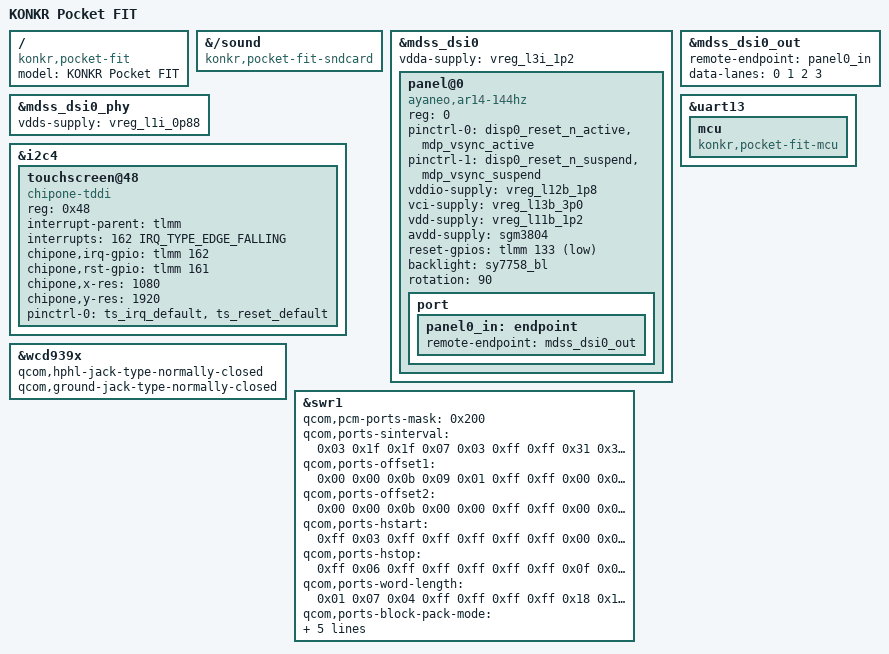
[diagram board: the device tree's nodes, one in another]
// SPDX-License-Identifier: BSD-3-Clause
/*
 * Copyright (c) 2023, Linaro Limited
 * Copyright (c) 2025, Kancy Joe <kancy2333@outlook.com>
 */

/dts-v1/;

#include "sm8650-ayaneo-common.dtsi"

/ {
	model = "KONKR Pocket FIT";
	compatible = "konkr,pocket-fit", "qcom,sm8650";
};

&{/sound} {
	compatible = "konkr,pocket-fit-sndcard";
};

&mdss_dsi0 {
	status = "okay";
	vdda-supply = <&vreg_l3i_1p2>;

	panel@0 {
		status = "okay";
		compatible = "ayaneo,ar14-144hz";
		reg = <0>;
		pinctrl-names = "default", "sleep";
		pinctrl-0 = <&disp0_reset_n_active>, <&mdp_vsync_active>;
		pinctrl-1 = <&disp0_reset_n_suspend>, <&mdp_vsync_suspend>;

		vddio-supply = <&vreg_l12b_1p8>;
		vci-supply = <&vreg_l13b_3p0>;
		vdd-supply = <&vreg_l11b_1p2>;
		avdd-supply = <&sgm3804>;

		reset-gpios = <&tlmm 133 GPIO_ACTIVE_LOW>;
		backlight = <&sy7758_bl>;
		rotation = <90>;

		port {
			panel0_in: endpoint {
				remote-endpoint = <&mdss_dsi0_out>;
			};
		};
	};
};

&mdss_dsi0_out {
	remote-endpoint = <&panel0_in>;
	data-lanes = <0 1 2 3>;
};

&mdss_dsi0_phy {
	vdds-supply = <&vreg_l1i_0p88>;

	status = "okay";
};

/*
 * Touchscreen: ChipOne ICNL9922C TDDI controller.
 *
 * Wiring taken verbatim from the stock Android devicetree
 * (qupv3_1 i2c@a90000 -> mainline &i2c4, device @0x48):
 *   - IRQ:   TLMM gpio162  (ts_irq_default pin state, defined in the dtsi)
 *   - reset: TLMM gpio161  (ts_reset_default pin state, defined in the dtsi)
 *   - power: shared with the panel rails (TDDI), already enabled above,
 *            so no dedicated regulator supply is needed here.
 *
 * Properties use the vendor "chipone-tddi" binding to match the ported
 * chipone_tddi driver. These may be migrated to a mainline-style binding
 * (interrupts + reset-gpios) once the driver port is finalized.
 */
&i2c4 {
	touchscreen@48 {
		compatible = "chipone-tddi";
		reg = <0x48>;

		interrupt-parent = <&tlmm>;
		interrupts = <162 IRQ_TYPE_EDGE_FALLING>;

		chipone,irq-gpio = <&tlmm 162 GPIO_ACTIVE_HIGH>;
		chipone,rst-gpio = <&tlmm 161 GPIO_ACTIVE_HIGH>;
		chipone,x-res = <1080>;
		chipone,y-res = <1920>;

		pinctrl-names = "default";
		pinctrl-0 = <&ts_irq_default>, <&ts_reset_default>;

		status = "okay";
	};
};

&uart13 {
	mcu {
		compatible = "konkr,pocket-fit-mcu";
	};
};

&wcd939x {
	qcom,hphl-jack-type-normally-closed;
	qcom,ground-jack-type-normally-closed;
};

/*
 * HPH PCM ("HiFi") playback, which the UCM profile uses on this board because
 * the PDM path hisses: the RX macro sends the PCM stream on master port 9 (the
 * stock Android swr-port-mapping, and the FIT Elite's), which sm8650.dtsi
 * leaves unconfigured. Give port 9 the PCM timing sm8650.dtsi has at port 8
 * (the FIT Elite's port 9 values) and the PCM data format enable.
 */
&swr1 {
	qcom,pcm-ports-mask = <0x200>;
	qcom,ports-sinterval =		/bits/ 16 <0x03 0x1f 0x1f 0x07 0x03 0xff 0xff 0x31 0x31 0xff 0xff 0xff>;
	qcom,ports-offset1 =		/bits/ 8 <0x00 0x00 0x0b 0x09 0x01 0xff 0xff 0x00 0x00 0xff 0xff 0xff>;
	qcom,ports-offset2 =		/bits/ 8 <0x00 0x00 0x0b 0x00 0x00 0xff 0xff 0x00 0x00 0xff 0xff 0xff>;
	qcom,ports-hstart =		/bits/ 8 <0xff 0x03 0xff 0xff 0xff 0xff 0xff 0x00 0x00 0xff 0xff 0xff>;
	qcom,ports-hstop =		/bits/ 8 <0xff 0x06 0xff 0xff 0xff 0xff 0xff 0x0f 0x0f 0xff 0xff 0xff>;
	qcom,ports-word-length =	/bits/ 8 <0x01 0x07 0x04 0xff 0xff 0xff 0xff 0x18 0x18 0xff 0xff 0xff>;
	qcom,ports-block-pack-mode =	/bits/ 8 <0xff 0x00 0x01 0xff 0xff 0xff 0xff 0x01 0x01 0xff 0xff 0xff>;
	qcom,ports-block-group-count =	/bits/ 8 <0xff 0xff 0xff 0x01 0x03 0xff 0xff 0x00 0x00 0xff 0xff 0xff>;
	qcom,ports-lane-control =	/bits/ 8 <0x01 0x00 0x00 0x00 0x00 0xff 0xff 0x01 0x01 0xff 0xff 0xff>;
};
